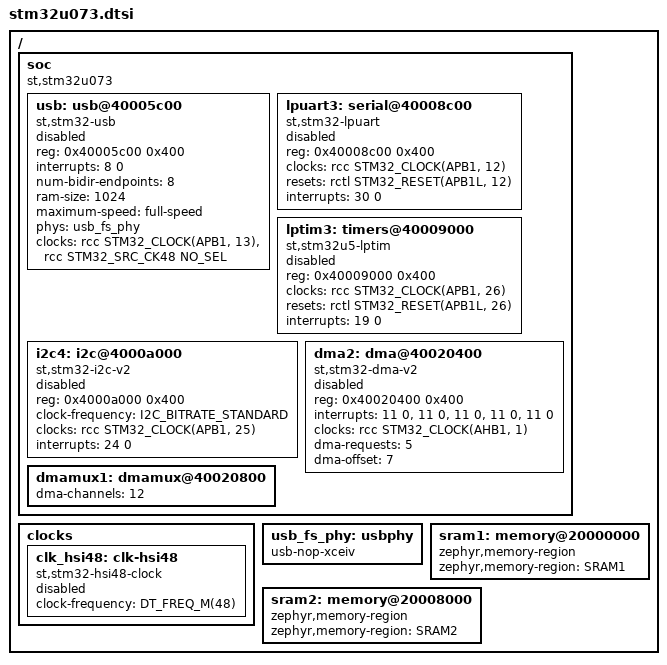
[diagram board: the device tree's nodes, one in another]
/*
 * Copyright (c) 2024 STMicroelectronics
 *
 * SPDX-License-Identifier: Apache-2.0
 */

#include <st/u0/stm32u031.dtsi>

/ {
	soc {
		compatible = "st,stm32u073", "st,stm32u0", "simple-bus";

		usb: usb@40005c00 {
			compatible = "st,stm32-usb";
			reg = <0x40005c00 0x400>;
			interrupts = <8 0>;
			interrupt-names = "usb";
			num-bidir-endpoints = <8>;
			ram-size = <1024>;
			maximum-speed = "full-speed";
			phys = <&usb_fs_phy>;
			clocks = <&rcc STM32_CLOCK(APB1, 13)>,
				 <&rcc STM32_SRC_CK48 NO_SEL>;
			status = "disabled";
		};

		lpuart3: serial@40008c00 {
			compatible = "st,stm32-lpuart", "st,stm32-uart";
			reg = <0x40008c00 0x400>;
			clocks = <&rcc STM32_CLOCK(APB1, 12)>;
			resets = <&rctl STM32_RESET(APB1L, 12)>;
			interrupts = <30 0>;
			interrupt-names = "combined";
			status = "disabled";
		};

		lptim3: timers@40009000 {
			compatible = "st,stm32u5-lptim", "st,stm32-lptim";
			reg = <0x40009000 0x400>;
			clocks = <&rcc STM32_CLOCK(APB1, 26)>;
			resets = <&rctl STM32_RESET(APB1L, 26)>;
			#address-cells = <1>;
			#size-cells = <0>;
			interrupts = <19 0>;
			interrupt-names = "combined";
			status = "disabled";
		};

		i2c4: i2c@4000a000 {
			compatible = "st,stm32-i2c-v2";
			reg = <0x4000a000 0x400>;
			clock-frequency = <I2C_BITRATE_STANDARD>;
			#address-cells = <1>;
			#size-cells = <0>;
			clocks = <&rcc STM32_CLOCK(APB1, 25)>;
			interrupts = <24 0>;
			interrupt-names = "combined";
			status = "disabled";
		};

		dma2: dma@40020400 {
			compatible = "st,stm32-dma-v2";
			reg = <0x40020400 0x400>;
			#dma-cells = <3>;
			interrupts = <11 0>, <11 0>, <11 0>, <11 0>, <11 0>;
			clocks = <&rcc STM32_CLOCK(AHB1, 1)>;
			dma-requests = <5>;
			dma-offset = <7>;
			status = "disabled";
		};

		dmamux1: dmamux@40020800 {
			dma-channels = <12>;
		};
	};

	clocks {
		clk_hsi48: clk-hsi48 {
			compatible = "st,stm32-hsi48-clock";
			#clock-cells = <0>;
			clock-frequency = <DT_FREQ_M(48)>;
			status = "disabled";
		};
	};

	usb_fs_phy: usbphy {
		compatible = "usb-nop-xceiv";
		#phy-cells = <0>;
	};

	sram1: memory@20000000 {
		compatible = "zephyr,memory-region", "mmio-sram";
		zephyr,memory-region = "SRAM1";
	};

	sram2: memory@20008000 {
		compatible = "zephyr,memory-region", "mmio-sram";
		zephyr,memory-region = "SRAM2";
	};
};
